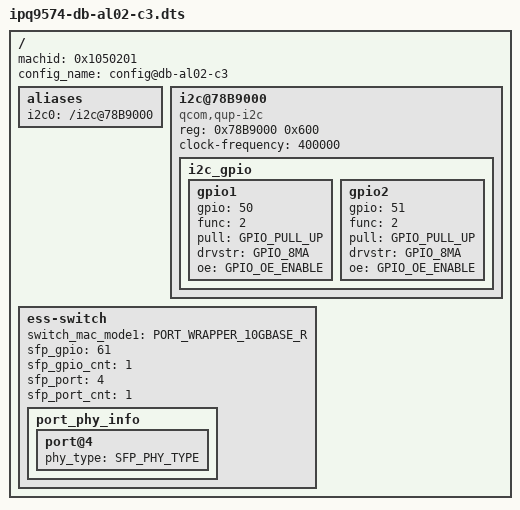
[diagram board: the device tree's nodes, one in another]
/*
 * Copyright (c) 2016-2021, The Linux Foundation. All rights reserved.
 *
 * This program is free software; you can redistribute it and/or modify
 * it under the terms of the GNU General Public License version 2 and
 * only version 2 as published by the Free Software Foundation.
 *
 * This program is distributed in the hope that it will be useful,
 * but WITHOUT ANY WARRANTY; without even the implied warranty of
 * MERCHANTABILITY or FITNESS FOR A PARTICULAR PURPOSE.  See the
 * GNU General Public License for more details.
 */

/dts-v1/;
#include "ipq9574-db-al02-c1.dts"
/ {
	machid = <0x1050201>;
	config_name = "config@db-al02-c3";

	aliases {
		i2c0 = "/i2c@78B9000";
	};

	i2c@78B9000 {
		compatible = "qcom,qup-i2c";
		#address-cells = <1>;
		#size-cells = <0>;
		reg = <0x78B9000 0x600>;
	        clock-frequency  = <400000>;
		i2c_gpio {
			gpio1 {
				gpio = <50>;
				func = <2>;
				pull = <GPIO_PULL_UP>;
				drvstr = <GPIO_8MA>;
				oe = <GPIO_OE_ENABLE>;
			};

			gpio2 {
				gpio = <51>;
				func = <2>;
				pull = <GPIO_PULL_UP>;
				drvstr = <GPIO_8MA>;
				oe = <GPIO_OE_ENABLE>;
			};
		};
	};

	ess-switch {
		/* Overriding port5 configuration to support SFP instead
		 * of QCA808x.
		 */
		/delete-property/qca808x_gpio;
		/delete-property/qca808x_gpio_cnt;
		switch_mac_mode1 = <PORT_WRAPPER_10GBASE_R>;
		sfp_gpio = <61>;
		sfp_gpio_cnt = <1>;
		sfp_port = <4>;
		sfp_port_cnt = <1>;
		port_phy_info {
			port@4 {
				/delete-property/phy_address;
				phy_type = <SFP_PHY_TYPE>;
			};
		};
	};
};
